# MLDR187 register map
File version: 1.4
CPU: MDR32F02, little endian
Registers are 32-bit, read-write, no defined reset value unless marked. A register's access mark holds for its fields unless they carry their own. Offsets are from the block's base; [hi:lo] are bit positions; {n}, {i} and the like mark numbered series; 'fields as' and 'values as' point back to an identical list.

## POWER — POWER description
Base 0x40058000
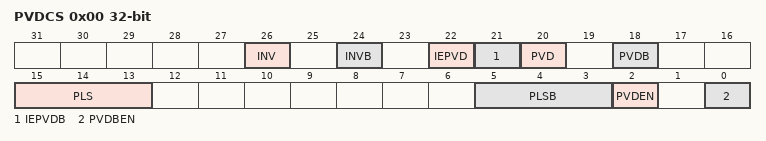
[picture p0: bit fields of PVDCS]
0x00 PVDCS — PVDCS description
  [26] INV — INV description
  [24] INVB — INVB description
  [22] IEPVD — IEPVD description
  [21] IEPVDB — IEPVDB description
  [20] PVD — PVD description
  [18] PVDB — PVDB description
  [15:13] PLS — PLS description
  [5:3] PLSB — PLSB description
  [2] PVDEN — PVDEN description
  [0] PVDBEN — PVDBEN description

## PORTA — PORTA description
Base 0x40080000
Same registers: PORTB 0x40088000, PORTC 0x40090000, PORTD 0x400F0000
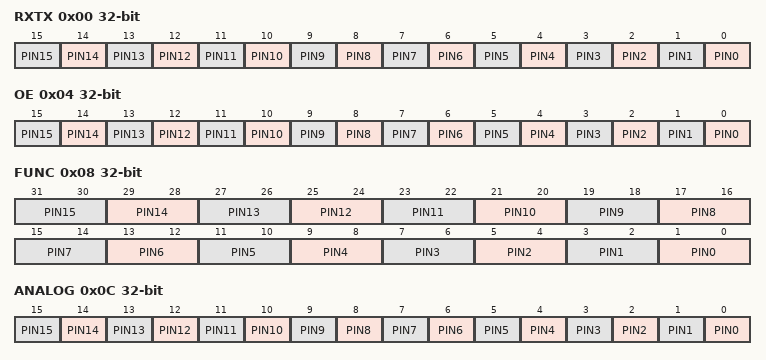
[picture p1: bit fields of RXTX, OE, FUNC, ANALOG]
0x00 RXTX — RXTX description
  [n] PIN{n} (n=0..15) — PIN{n} description
0x04 OE — OE description
  [n] PIN{n} (n=0..15) — PIN{n} description
0x08 FUNC — FUNC description
  [2n+1:2n] PIN{n} (n=0..15) — PIN{n} description
0x0C ANALOG — ANALOG description
  [n] PIN{n} (n=0..15) — PIN{n} description
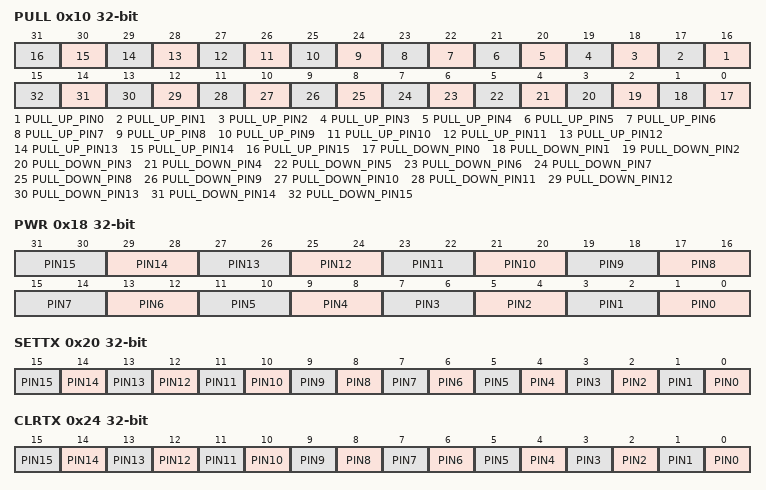
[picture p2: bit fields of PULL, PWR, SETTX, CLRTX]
0x10 PULL — PULL description
  [n+16] PULL_UP_PIN{n} (n=0..15) — PULL_UP_PIN{n} description. Rev2
  [n] PULL_DOWN_PIN{n} (n=0..15) — PULL_DOWN_PIN{n} description
0x18 PWR — PWR description
  [2n+1:2n] PIN{n} (n=0..15) — PIN{n} description
0x20 SETTX — SETTX description
  [n] PIN{n} (n=0..15) — PIN{n} description
0x24 CLRTX — CLRTX description
  [n] PIN{n} (n=0..15) — PIN{n} description
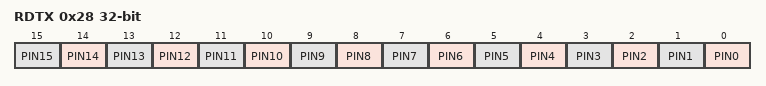
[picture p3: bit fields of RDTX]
0x28 RDTX — RDTX description
  [n] PIN{n} (n=0..15) — PIN{n} description

## SPI1 — SPI1 description
Base 0x40000000
Same registers: SPI2 0x400C8000, SPI3 0x400D0000
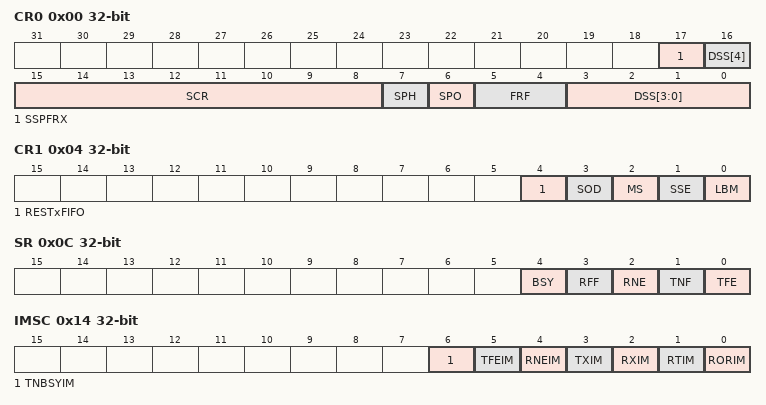
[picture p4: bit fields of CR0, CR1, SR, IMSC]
0x00 CR0 — CR0 description
  [17] SSPFRX — SSPFRX description. Rev2
  [16] DSS[4] — DSS[4] description. Rev2
  [15:8] SCR — SCR description
  [7] SPH — SPH description
  [6] SPO — SPO description
  [5:4] FRF — FRF description
  [3:0] DSS[3:0] — DSS[3:0] description
0x04 CR1 — CR1 description
  [4] RESTxFIFO — RESTxFIFO description. Rev2
  [3] SOD — SOD description
  [2] MS — MS description
  [1] SSE — SSE description
  [0] LBM — LBM description
0x08 DR — DR description
  [31:0] DATA — DATA description. Rev2
0x0C SR — SR description
  [4] BSY — BSY description
  [3] RFF — RFF description
  [2] RNE — RNE description
  [1] TNF — TNF description
  [0] TFE — TFE description
0x10 CPSR — CPSR description
  [7:0] DVSR — DVSR description
0x14 IMSC — IMSC description
  [6] TNBSYIM — TNBSYIM description. Rev2
  [5] TFEIM — TFEIM description. Rev2
  [4] RNEIM — RNEIM description. Rev2
  [3] TXIM — TXIM description
  [2] RXIM — RXIM description
  [1] RTIM — RTIM description
  [0] RORIM — RORIM description
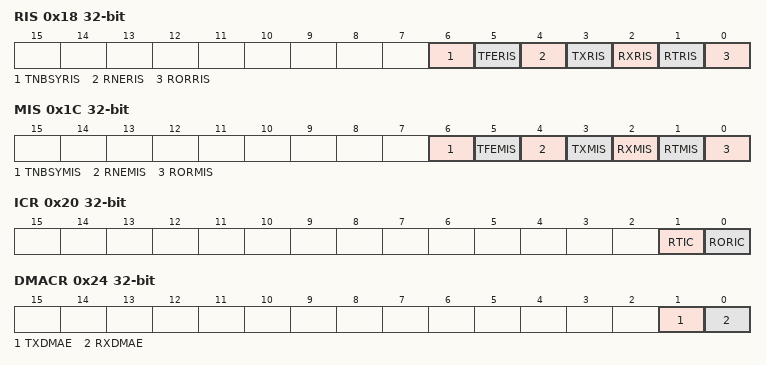
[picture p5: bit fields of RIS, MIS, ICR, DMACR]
0x18 RIS — RIS description
  [6] TNBSYRIS — TNBSYRIS description. Rev2
  [5] TFERIS — TFERIS description. Rev2
  [4] RNERIS — RNERIS description. Rev2
  [3] TXRIS — TXRIS description
  [2] RXRIS — RXRIS description
  [1] RTRIS — RTRIS description
  [0] RORRIS — RORRIS description
0x1C MIS — MIS description
  [6] TNBSYMIS — TNBSYMIS description. Rev2
  [5] TFEMIS — TFEMIS description. Rev2
  [4] RNEMIS — RNEMIS description. Rev2
  [3] TXMIS — TXMIS description
  [2] RXMIS — RXMIS description
  [1] RTMIS — RTMIS description
  [0] RORMIS — RORMIS description
0x20 ICR — ICR description
  [1] RTIC — RTIC description
  [0] RORIC — RORIC description
0x24 DMACR — DMACR description
  [1] TXDMAE — TXDMAE description
  [0] RXDMAE — RXDMAE description

## TIMER1 — TIMER1 description
Base 0x40070000
Same registers: TIMER2 0x40078000, TIMER3 0x400D8000, TIMER4 0x400E0000
0x00 CNT — CNT description
0x04 PSG — PSG description
  [15:0] PSG
0x08 ARR — ARR description
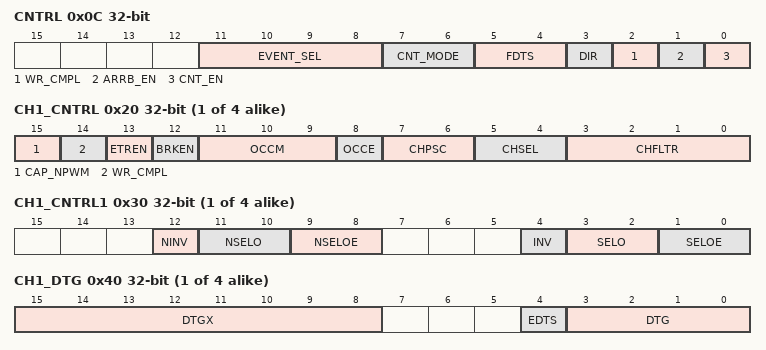
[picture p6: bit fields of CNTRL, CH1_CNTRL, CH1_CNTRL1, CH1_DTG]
0x0C CNTRL — CNTRL description
  [11:8] EVENT_SEL — EVENT_SEL description
  [7:6] CNT_MODE — CNT_MODE description
  [5:4] FDTS — FDTS description
  [3] DIR — DIR description
  [2] WR_CMPL — WR_CMPL description
  [1] ARRB_EN — ARRB_EN description
  [0] CNT_EN — CNT_EN description
{0xC+4i} CCR{i} (i=1..4) — CCR{i} description
{0x1C+4i} CH{i}_CNTRL (i=1..4) — CH{i}_CNTRL description
  [15] CAP_NPWM — CAP_NPWM description
  [14] WR_CMPL — WR_CMPL description
  [13] ETREN — ETREN description
  [12] BRKEN — BRKEN description
  [11:9] OCCM — OCCM description
  [8] OCCE — OCCE description
  [7:6] CHPSC — CHPSC description
  [5:4] CHSEL — CHSEL description
  [3:0] CHFLTR — CHFLTR description
{0x2C+4i} CH{i}_CNTRL1 (i=1..4) — CH{i}_CNTRL1 description
  [12] NINV — NINV description
  [11:10] NSELO — NSELO description
  [9:8] NSELOE — NSELOE description
  [4] INV — INV description
  [3:2] SELO — SELO description
  [1:0] SELOE — SELOE description
{0x3C+4i} CH{i}_DTG (i=1..4) — CH{i}_DTG description
  [15:8] DTGX — DTGX description
  [4] EDTS — EDTS description
  [3:0] DTG — DTG description
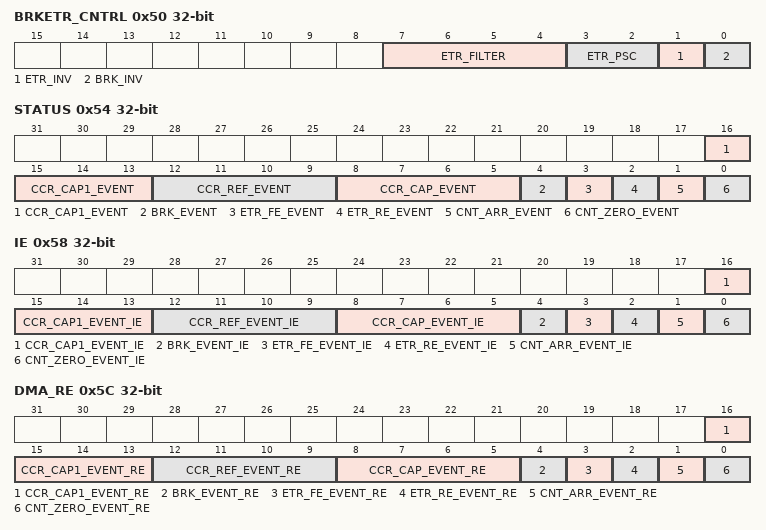
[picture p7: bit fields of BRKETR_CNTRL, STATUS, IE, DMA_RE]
0x50 BRKETR_CNTRL — BRKETR_CNTRL description
  [7:4] ETR_FILTER — ETR_FILTER description
  [3:2] ETR_PSC — ETR_PSC description
  [1] ETR_INV — ETR_INV description
  [0] BRK_INV — BRK_INV description
0x54 STATUS — STATUS description
  [16:13] CCR_CAP1_EVENT — CCR_CAP1_EVENT description
  [12:9] CCR_REF_EVENT — CCR_REF_EVENT description
  [8:5] CCR_CAP_EVENT — CCR_CAP_EVENT description
  [4] BRK_EVENT — BRK_EVENT description
  [3] ETR_FE_EVENT — ETR_FE_EVENT description
  [2] ETR_RE_EVENT — ETR_RE_EVENT description
  [1] CNT_ARR_EVENT — CNT_ARR_EVENT description
  [0] CNT_ZERO_EVENT — CNT_ZERO_EVENT description
0x58 IE — IE description
  [16:13] CCR_CAP1_EVENT_IE — CCR_CAP1_EVENT_IE description
  [12:9] CCR_REF_EVENT_IE — CCR_REF_EVENT_IE description
  [8:5] CCR_CAP_EVENT_IE — CCR_CAP_EVENT_IE description
  [4] BRK_EVENT_IE — BRK_EVENT_IE description
  [3] ETR_FE_EVENT_IE — ETR_FE_EVENT_IE description
  [2] ETR_RE_EVENT_IE — ETR_RE_EVENT_IE description
  [1] CNT_ARR_EVENT_IE — CNT_ARR_EVENT_IE description
  [0] CNT_ZERO_EVENT_IE — CNT_ZERO_EVENT_IE description
0x5C DMA_RE — DMA_RE description
  [16:13] CCR_CAP1_EVENT_RE — CCR_CAP1_EVENT_RE description
  [12:9] CCR_REF_EVENT_RE — CCR_REF_EVENT_RE description
  [8:5] CCR_CAP_EVENT_RE — CCR_CAP_EVENT_RE description
  [4] BRK_EVENT_RE — BRK_EVENT_RE description
  [3] ETR_FE_EVENT_RE — ETR_FE_EVENT_RE description
  [2] ETR_RE_EVENT_RE — ETR_RE_EVENT_RE description
  [1] CNT_ARR_EVENT_RE — CNT_ARR_EVENT_RE description
  [0] CNT_ZERO_EVENT_RE — CNT_ZERO_EVENT_RE description
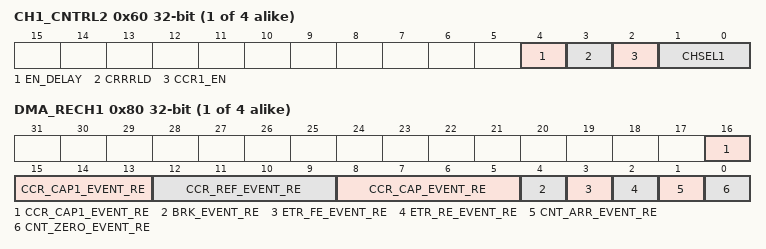
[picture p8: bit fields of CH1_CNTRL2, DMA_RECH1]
{0x5C+4i} CH{i}_CNTRL2 (i=1..4) — CH{i}_CNTRL2 description
  [4] EN_DELAY — EN_DELAY description
  [3] CRRRLD — CRRRLD description
  [2] CCR1_EN — CCR1_EN description
  [1:0] CHSEL1 — CHSEL1 description
0x70 CCR11 — CCR11 description
0x74 CCR21 — CCR21 description
0x78 CCR31 — CCR31 description
0x7C CCR41 — CCR41 description
{0x7C+4i} DMA_RECH{i} (i=1..4) — DMA_RECH{i} description
  fields as DMA_RE
